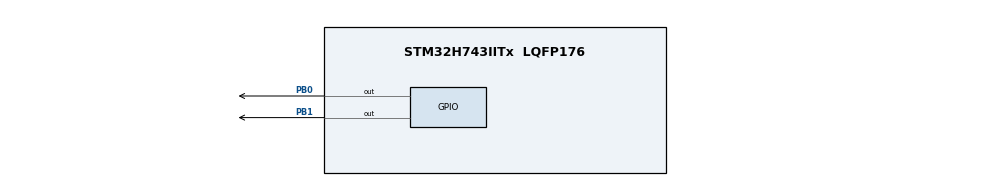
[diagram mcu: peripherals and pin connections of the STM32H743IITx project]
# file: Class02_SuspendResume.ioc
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FREERTOS.Tasks01=defaultTask,0,128,StartDefaultTask,Default,NULL,Dynamic,NULL,NULL;Blink_PB0,0,128,blink01,Default,NULL,Dynamic,NULL,NULL;Blink_PB1,0,128,blink02,Default,NULL,Dynamic,NULL,NULL
Mcu.Family=STM32H7
Mcu.Name=STM32H743IITx
Mcu.Package=LQFP176
NVIC.PriorityGroup=NVIC_PRIORITYGROUP_4
PB0.Signal=GPIO_Output
PB1.Signal=GPIO_Output
PH0-OSC_IN\ (PH0).Mode=HSE-External-Oscillator
PH0-OSC_IN\ (PH0).Signal=RCC_OSC_IN
PH1-OSC_OUT\ (PH1).Mode=HSE-External-Oscillator
PH1-OSC_OUT\ (PH1).Signal=RCC_OSC_OUT
ProjectManager.HeapSize=0x200
ProjectManager.StackSize=0x400
ProjectManager.TargetToolchain=MDK-ARM V5
RCC.ADCFreq_Value=50390625
RCC.APB1Freq_Value=100000000
RCC.APB2Freq_Value=100000000
RCC.APB3Freq_Value=100000000
RCC.APB4Freq_Value=100000000
RCC.CortexFreq_Value=400000000
RCC.D1PPRE=RCC_APB3_DIV2
RCC.D2PPRE1=RCC_APB1_DIV2
RCC.D2PPRE2=RCC_APB2_DIV2
RCC.D3PPRE=RCC_APB4_DIV2
RCC.DIVM1=2
RCC.DIVN1=64
RCC.HCLKFreq_Value=200000000
RCC.HPRE=RCC_HCLK_DIV2
RCC.PLLSourceVirtual=RCC_PLLSOURCE_HSE
RCC.SYSCLKFreq_VALUE=400000000
RCC.SYSCLKSource=RCC_SYSCLKSOURCE_PLLCLK
RCC.USBFreq_Value=400000000
VP_FREERTOS_VS_ENABLE.Mode=Enabled
board=custom

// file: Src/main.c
/* USER CODE BEGIN Header */
/**
  ******************************************************************************
  * @file           : main.c
  * @brief          : Main program body
  ******************************************************************************
  * This notice applies to any and all portions of this file
  * that are not between comment pairs USER CODE BEGIN and
  * USER CODE END. Other portions of this file, whether
  * inserted by the user or by software development tools
  * are owned by their respective copyright owners.
  *
  * Copyright (c) 2018 STMicroelectronics International N.V.
  * All rights reserved.
  *
  * Redistribution and use in source and binary forms, with or without
  * modification, are permitted, provided that the following conditions are met:
  *
  * 1. Redistribution of source code must retain the above copyright notice,
  *    this list of conditions and the following disclaimer.
  * 2. Redistributions in binary form must reproduce the above copyright notice,
  *    this list of conditions and the following disclaimer in the documentation
  *    and/or other materials provided with the distribution.
  * 3. Neither the name of STMicroelectronics nor the names of other
  *    contributors to this software may be used to endorse or promote products
  *    derived from this software without specific written permission.
  * 4. This software, including modifications and/or derivative works of this
  *    software, must execute solely and exclusively on microcontroller or
  *    microprocessor devices manufactured by or for STMicroelectronics.
  * 5. Redistribution and use of this software other than as permitted under
  *    this license is void and will automatically terminate your rights under
  *    this license.
  *
  * THIS SOFTWARE IS PROVIDED BY STMICROELECTRONICS AND CONTRIBUTORS "AS IS"
  * AND ANY EXPRESS, IMPLIED OR STATUTORY WARRANTIES, INCLUDING, BUT NOT
  * LIMITED TO, THE IMPLIED WARRANTIES OF MERCHANTABILITY, FITNESS FOR A
  * PARTICULAR PURPOSE AND NON-INFRINGEMENT OF THIRD PARTY INTELLECTUAL PROPERTY
  * RIGHTS ARE DISCLAIMED TO THE FULLEST EXTENT PERMITTED BY LAW. IN NO EVENT
  * SHALL STMICROELECTRONICS OR CONTRIBUTORS BE LIABLE FOR ANY DIRECT, INDIRECT,
  * INCIDENTAL, SPECIAL, EXEMPLARY, OR CONSEQUENTIAL DAMAGES (INCLUDING, BUT NOT
  * LIMITED TO, PROCUREMENT OF SUBSTITUTE GOODS OR SERVICES; LOSS OF USE, DATA,
  * OR PROFITS; OR BUSINESS INTERRUPTION) HOWEVER CAUSED AND ON ANY THEORY OF
  * LIABILITY, WHETHER IN CONTRACT, STRICT LIABILITY, OR TORT (INCLUDING
  * NEGLIGENCE OR OTHERWISE) ARISING IN ANY WAY OUT OF THE USE OF THIS SOFTWARE,
  * EVEN IF ADVISED OF THE POSSIBILITY OF SUCH DAMAGE.
  *
  ******************************************************************************
  */
/* USER CODE END Header */

#include "main.h"
#include "cmsis_os.h"

osThreadId defaultTaskHandle;
osThreadId Blink_PB0Handle;
osThreadId Blink_PB1Handle;

void SystemClock_Config(void);
static void MX_GPIO_Init(void);
void StartDefaultTask(void const * argument);
void blink01(void const * argument);
void blink02(void const * argument);

int main(void)
{

  /* MCU Configuration--------------------------------------------------------*/

  /* Reset of all peripherals, Initializes the Flash interface and the Systick. */
  HAL_Init();

  /* Configure the system clock */
  SystemClock_Config();

  /* Initialize all configured peripherals */
  MX_GPIO_Init();

  /* Create the thread(s) */
  /* definition and creation of defaultTask */
  osThreadDef(defaultTask, StartDefaultTask, osPriorityNormal, 0, 128);
  defaultTaskHandle = osThreadCreate(osThread(defaultTask), NULL);

  /* definition and creation of Blink_PB0 */
  osThreadDef(Blink_PB0, blink01, osPriorityNormal, 0, 128);
  Blink_PB0Handle = osThreadCreate(osThread(Blink_PB0), NULL);

  /* definition and creation of Blink_PB1 */
  osThreadDef(Blink_PB1, blink02, osPriorityNormal, 0, 128);
  Blink_PB1Handle = osThreadCreate(osThread(Blink_PB1), NULL);

  /* Start scheduler */
  osKernelStart();

  /* We should never get here as control is now taken by the scheduler */

  /* Infinite loop */
  while (1)
  {

  }
}

void SystemClock_Config(void)
{
  RCC_OscInitTypeDef RCC_OscInitStruct = {0};
  RCC_ClkInitTypeDef RCC_ClkInitStruct = {0};

  /**Supply configuration update enable
  */
  MODIFY_REG(PWR->CR3, PWR_CR3_SCUEN, 0);
  /**Configure the main internal regulator output voltage
  */
  __HAL_PWR_VOLTAGESCALING_CONFIG(PWR_REGULATOR_VOLTAGE_SCALE1);

  while ((PWR->D3CR & (PWR_D3CR_VOSRDY)) != PWR_D3CR_VOSRDY)
  {

  }
  /**Initializes the CPU, AHB and APB busses clocks
  */
  RCC_OscInitStruct.OscillatorType = RCC_OSCILLATORTYPE_HSE;
  RCC_OscInitStruct.HSEState = RCC_HSE_ON;
  RCC_OscInitStruct.PLL.PLLState = RCC_PLL_ON;
  RCC_OscInitStruct.PLL.PLLSource = RCC_PLLSOURCE_HSE;
  RCC_OscInitStruct.PLL.PLLM = 2;
  RCC_OscInitStruct.PLL.PLLN = 64;
  RCC_OscInitStruct.PLL.PLLP = 2;
  RCC_OscInitStruct.PLL.PLLQ = 2;
  RCC_OscInitStruct.PLL.PLLR = 2;
  RCC_OscInitStruct.PLL.PLLRGE = RCC_PLL1VCIRANGE_3;
  RCC_OscInitStruct.PLL.PLLVCOSEL = RCC_PLL1VCOWIDE;
  RCC_OscInitStruct.PLL.PLLFRACN = 0;
  if (HAL_RCC_OscConfig(&RCC_OscInitStruct) != HAL_OK)
  {
    Error_Handler();
  }
  /**Initializes the CPU, AHB and APB busses clocks
  */
  RCC_ClkInitStruct.ClockType = RCC_CLOCKTYPE_HCLK|RCC_CLOCKTYPE_SYSCLK
                              |RCC_CLOCKTYPE_PCLK1|RCC_CLOCKTYPE_PCLK2
                              |RCC_CLOCKTYPE_D3PCLK1|RCC_CLOCKTYPE_D1PCLK1;
  RCC_ClkInitStruct.SYSCLKSource = RCC_SYSCLKSOURCE_PLLCLK;
  RCC_ClkInitStruct.SYSCLKDivider = RCC_SYSCLK_DIV1;
  RCC_ClkInitStruct.AHBCLKDivider = RCC_HCLK_DIV2;
  RCC_ClkInitStruct.APB3CLKDivider = RCC_APB3_DIV2;
  RCC_ClkInitStruct.APB1CLKDivider = RCC_APB1_DIV2;
  RCC_ClkInitStruct.APB2CLKDivider = RCC_APB2_DIV2;
  RCC_ClkInitStruct.APB4CLKDivider = RCC_APB4_DIV2;

  if (HAL_RCC_ClockConfig(&RCC_ClkInitStruct, FLASH_LATENCY_2) != HAL_OK)
  {
    Error_Handler();
  }
}

static void MX_GPIO_Init(void)
{
  GPIO_InitTypeDef GPIO_InitStruct = {0};

  /* GPIO Ports Clock Enable */
  __HAL_RCC_GPIOH_CLK_ENABLE();
  __HAL_RCC_GPIOB_CLK_ENABLE();

  /*Configure GPIO pin Output Level */
  HAL_GPIO_WritePin(GPIOB, GPIO_PIN_0|GPIO_PIN_1, GPIO_PIN_RESET);

  /*Configure GPIO pins : PB0 PB1 */
  GPIO_InitStruct.Pin = GPIO_PIN_0|GPIO_PIN_1;
  GPIO_InitStruct.Mode = GPIO_MODE_OUTPUT_PP;
  GPIO_InitStruct.Pull = GPIO_NOPULL;
  GPIO_InitStruct.Speed = GPIO_SPEED_FREQ_LOW;
  HAL_GPIO_Init(GPIOB, &GPIO_InitStruct);

}

void StartDefaultTask(void const * argument)
{

  for(;;)
  {
    osDelay(1);
  }
}

void blink01(void const * argument)
{
  /* USER CODE BEGIN blink01 */
	int i = 0;
  /* Infinite loop */
  for(;;)
  {
		if(i == 10)
			vTaskSuspend(Blink_PB1Handle);
		if(i == 20)
			vTaskResume(Blink_PB1Handle);
		HAL_GPIO_TogglePin(GPIOB,GPIO_PIN_1);
    osDelay(500);
		i++;
  }
  /* USER CODE END blink01 */
}

void blink02(void const * argument)
{
  /* USER CODE BEGIN blink02 */
  /* Infinite loop */
  for(;;)
  {
		HAL_GPIO_TogglePin(GPIOB,GPIO_PIN_0);
    osDelay(1000);

  }
  /* USER CODE END blink02 */
}

void Error_Handler(void)
{
}

/************************ (C) COPYRIGHT STMicroelectronics *****END OF FILE****/
